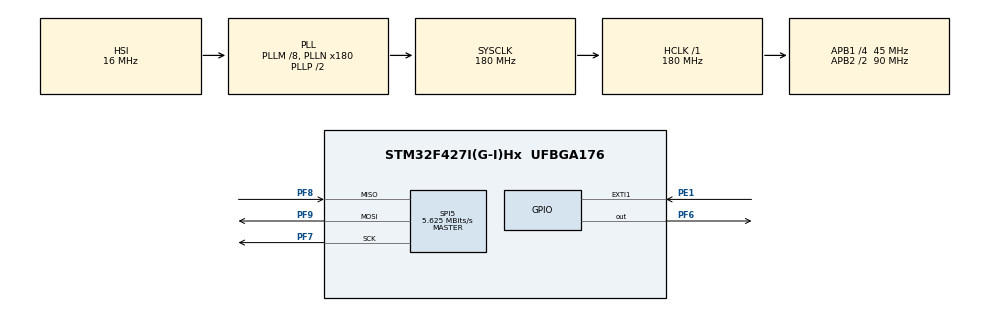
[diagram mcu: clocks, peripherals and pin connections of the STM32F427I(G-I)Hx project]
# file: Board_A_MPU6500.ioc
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Mcu.Family=STM32F4
Mcu.Name=STM32F427I(G-I)Hx
Mcu.Package=UFBGA176
NVIC.EXTI1_IRQn=true\:0\:0\:false\:false\:true\:true\:true\:true
NVIC.PriorityGroup=NVIC_PRIORITYGROUP_4
PA13.Mode=Serial_Wire
PA13.Signal=SYS_JTMS-SWDIO
PA14.Mode=Serial_Wire
PA14.Signal=SYS_JTCK-SWCLK
PE1.Signal=GPXTI1
PF6.PinState=GPIO_PIN_SET
PF6.Signal=GPIO_Output
PF7.Mode=Full_Duplex_Master
PF7.Signal=SPI5_SCK
PF8.Mode=Full_Duplex_Master
PF8.Signal=SPI5_MISO
PF9.Mode=Full_Duplex_Master
PF9.Signal=SPI5_MOSI
PH0/OSC_IN.Mode=HSE-External-Oscillator
PH0/OSC_IN.Signal=RCC_OSC_IN
PH1/OSC_OUT.Mode=HSE-External-Oscillator
PH1/OSC_OUT.Signal=RCC_OSC_OUT
ProjectManager.HeapSize=0x200
ProjectManager.StackSize=0x400
ProjectManager.TargetToolchain=CMake
RCC.48MHZClocksFreq_Value=90000000
RCC.AHBFreq_Value=180000000
RCC.APB1CLKDivider=RCC_HCLK_DIV4
RCC.APB1Freq_Value=45000000
RCC.APB1TimFreq_Value=90000000
RCC.APB2CLKDivider=RCC_HCLK_DIV2
RCC.APB2Freq_Value=90000000
RCC.APB2TimFreq_Value=180000000
RCC.CortexFreq_Value=180000000
RCC.HCLKFreq_Value=180000000
RCC.HSE_VALUE=25000000
RCC.HSI_VALUE=16000000
RCC.LSE_VALUE=32768
RCC.PLLM=8
RCC.PLLN=180
RCC.SYSCLKFreq_VALUE=180000000
RCC.SYSCLKSource=RCC_SYSCLKSOURCE_PLLCLK
RCC.VCOOutputFreq_Value=360000000
SPI5.BaudRatePrescaler=SPI_BAUDRATEPRESCALER_16
SPI5.CalculateBaudRate=5.625 MBits/s
SPI5.Direction=SPI_DIRECTION_2LINES
SPI5.Mode=SPI_MODE_MASTER
SPI5.VirtualType=VM_MASTER
board=custom

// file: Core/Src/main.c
/* USER CODE BEGIN Header */
/**
  ******************************************************************************
  * @file           : main.c
  * @brief          : Main program body
  ******************************************************************************
  * @attention
  *
  * Copyright (c) 2026 STMicroelectronics.
  * All rights reserved.
  *
  * This software is licensed under terms that can be found in the LICENSE file
  * in the root directory of this software component.
  * If no LICENSE file comes with this software, it is provided AS-IS.
  *
  ******************************************************************************
  */
/* USER CODE END Header */
#include "main.h"
#include "spi.h"
#include "gpio.h"
#include<math.h>

void SystemClock_Config(void);

float roll = 0.0f;
float pitch = 0.0f;
float yaw = 0.0f;

float ax_g, ay_g, az_g;
float gx_dps, gy_dps, gz_dps;

float dt = 0.01f;
uint8_t MPU6500_ReadReg(uint8_t reg)
{
  uint8_t tx[2] = {reg | 0x80, 0xFF};
  uint8_t rx[2] = {0};

  HAL_GPIO_WritePin(GPIOF, GPIO_PIN_6, GPIO_PIN_RESET);
  HAL_SPI_TransmitReceive(&hspi5, tx, rx, 2, 100);
  HAL_GPIO_WritePin(GPIOF, GPIO_PIN_6, GPIO_PIN_SET);

  return rx[1];
}

void MPU6500_ReadData(int16_t *ax, int16_t *ay, int16_t *az,
                      int16_t *gx, int16_t *gy, int16_t *gz)
{
  uint8_t data[14];
  uint8_t reg = 0x3B | 0x80;
  uint8_t dummy[14] = {0};

  HAL_GPIO_WritePin(GPIOF, GPIO_PIN_6, GPIO_PIN_RESET);
  HAL_SPI_Transmit(&hspi5, &reg, 1, 100);
  HAL_SPI_TransmitReceive(&hspi5, dummy, data, 14, 100);
  HAL_GPIO_WritePin(GPIOF, GPIO_PIN_6, GPIO_PIN_SET);

  *ax = (int16_t)((data[0] << 8) | data[1]);
  *ay = (int16_t)((data[2] << 8) | data[3]);
  *az = (int16_t)((data[4] << 8) | data[5]);

  *gx = (int16_t)((data[8] << 8) | data[9]);
  *gy = (int16_t)((data[10] << 8) | data[11]);
  *gz = (int16_t)((data[12] << 8) | data[13]);
}
void MPU6500_CalculateAngle(int16_t ax, int16_t ay, int16_t az,
                            int16_t gx, int16_t gy, int16_t gz)
{
  float acc_roll;
  float acc_pitch;

  ax_g = ax / 16384.0f;
  ay_g = ay / 16384.0f;
  az_g = az / 16384.0f;

  gx_dps = gx / 131.0f;
  gy_dps = gy / 131.0f;
  gz_dps = gz / 131.0f;

  acc_roll = atan2f(ay_g, az_g) * 57.29578f;
  acc_pitch = atan2f(-ax_g, sqrtf(ay_g * ay_g + az_g * az_g))
              * 57.29578f;

  roll = 0.98f * (roll + gx_dps * dt) + 0.02f * acc_roll;
  pitch = 0.98f * (pitch + gy_dps * dt) + 0.02f * acc_pitch;

  yaw += gz_dps * dt;
}

int main(void)
{

  /* MCU Configuration--------------------------------------------------------*/

  /* Reset of all peripherals, Initializes the Flash interface and the Systick. */
  HAL_Init();

  /* Configure the system clock */
  SystemClock_Config();

  /* Initialize all configured peripherals */
  MX_GPIO_Init();
  MX_SPI5_Init();
  /* USER CODE BEGIN 2 */
  int16_t ax, ay, az;
  int16_t gx, gy, gz;
  HAL_Delay(100);

  uint8_t mpu_id = MPU6500_ReadReg(0x75);

  /* USER CODE END 2 */

  /* Infinite loop */
  /* USER CODE BEGIN WHILE */
  while (1)
  {
    MPU6500_ReadData(&ax, &ay, &az, &gx, &gy, &gz);

    MPU6500_CalculateAngle(ax, ay, az, gx, gy, gz);

    HAL_Delay(10);
  }
  /* USER CODE END 3 */
}

void SystemClock_Config(void)
{
  RCC_OscInitTypeDef RCC_OscInitStruct = {0};
  RCC_ClkInitTypeDef RCC_ClkInitStruct = {0};

  /** Configure the main internal regulator output voltage
  */
  __HAL_RCC_PWR_CLK_ENABLE();
  __HAL_PWR_VOLTAGESCALING_CONFIG(PWR_REGULATOR_VOLTAGE_SCALE1);

  /** Initializes the RCC Oscillators according to the specified parameters
  * in the RCC_OscInitTypeDef structure.
  */
  RCC_OscInitStruct.OscillatorType = RCC_OSCILLATORTYPE_HSI;
  RCC_OscInitStruct.HSIState = RCC_HSI_ON;
  RCC_OscInitStruct.HSICalibrationValue = RCC_HSICALIBRATION_DEFAULT;
  RCC_OscInitStruct.PLL.PLLState = RCC_PLL_ON;
  RCC_OscInitStruct.PLL.PLLSource = RCC_PLLSOURCE_HSI;
  RCC_OscInitStruct.PLL.PLLM = 8;
  RCC_OscInitStruct.PLL.PLLN = 180;
  RCC_OscInitStruct.PLL.PLLP = RCC_PLLP_DIV2;
  RCC_OscInitStruct.PLL.PLLQ = 4;
  if (HAL_RCC_OscConfig(&RCC_OscInitStruct) != HAL_OK)
  {
    Error_Handler();
  }

  /** Activate the Over-Drive mode
  */
  if (HAL_PWREx_EnableOverDrive() != HAL_OK)
  {
    Error_Handler();
  }

  /** Initializes the CPU, AHB and APB buses clocks
  */
  RCC_ClkInitStruct.ClockType = RCC_CLOCKTYPE_HCLK|RCC_CLOCKTYPE_SYSCLK
                              |RCC_CLOCKTYPE_PCLK1|RCC_CLOCKTYPE_PCLK2;
  RCC_ClkInitStruct.SYSCLKSource = RCC_SYSCLKSOURCE_PLLCLK;
  RCC_ClkInitStruct.AHBCLKDivider = RCC_SYSCLK_DIV1;
  RCC_ClkInitStruct.APB1CLKDivider = RCC_HCLK_DIV4;
  RCC_ClkInitStruct.APB2CLKDivider = RCC_HCLK_DIV2;

  if (HAL_RCC_ClockConfig(&RCC_ClkInitStruct, FLASH_LATENCY_5) != HAL_OK)
  {
    Error_Handler();
  }
}

void Error_Handler(void)
{
  __disable_irq();
  while (1)
  {
  }
}
